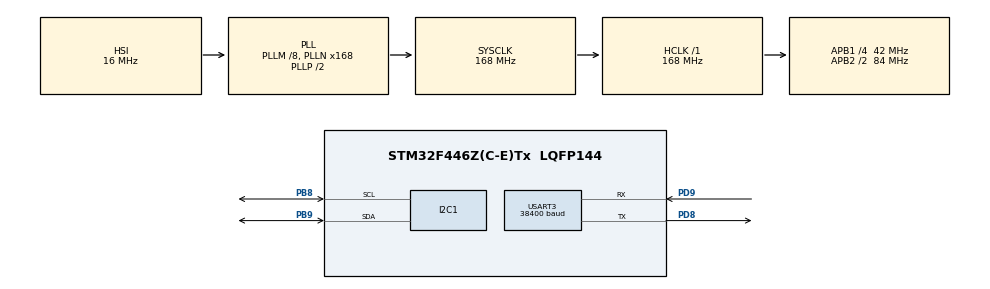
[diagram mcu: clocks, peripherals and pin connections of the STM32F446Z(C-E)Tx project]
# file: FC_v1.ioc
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FREERTOS.Tasks01=defaultTask,24,128,StartDefaultTask,Default,NULL,Dynamic,NULL,NULL;Iridium02,8,128,StartIridium02,Default,NULL,Dynamic,NULL,NULL;LSM6DSR03,8,128,StartLSM6DSR03,Default,NULL,Dynamic,NULL,NULL
FREERTOS.configUSE_NEWLIB_REENTRANT=1
Mcu.Family=STM32F4
Mcu.Name=STM32F446Z(C-E)Tx
Mcu.Package=LQFP144
NVIC.PriorityGroup=NVIC_PRIORITYGROUP_4
NVIC.RTC_Alarm_IRQn=true\:5\:0\:false\:false\:true\:true\:true\:true
NVIC.TIM1_UP_TIM10_IRQn=true\:15\:0\:false\:false\:true\:false\:false\:true
NVIC.TimeBase=TIM1_UP_TIM10_IRQn
NVIC.TimeBaseIP=TIM1
PB8.Mode=I2C
PB8.Signal=I2C1_SCL
PB9.Mode=I2C
PB9.Signal=I2C1_SDA
PD8.Mode=Asynchronous
PD8.Signal=USART3_TX
PD9.Mode=Asynchronous
PD9.Signal=USART3_RX
ProjectManager.HeapSize=0x200
ProjectManager.StackSize=0x400
ProjectManager.TargetToolchain=STM32CubeIDE
RCC.48MHZClocksFreq_Value=24000000
RCC.AHBFreq_Value=168000000
RCC.APB1CLKDivider=RCC_HCLK_DIV4
RCC.APB1Freq_Value=42000000
RCC.APB1TimFreq_Value=84000000
RCC.APB2CLKDivider=RCC_HCLK_DIV2
RCC.APB2Freq_Value=84000000
RCC.APB2TimFreq_Value=168000000
RCC.CortexFreq_Value=168000000
RCC.HCLKFreq_Value=168000000
RCC.HSE_VALUE=8000000
RCC.HSI_VALUE=16000000
RCC.PLLM=8
RCC.PLLMUL=RCC_PLL_MUL9
RCC.PLLN=168
RCC.PLLQ=7
RCC.PRESCALERUSB=RCC_USBCLKSOURCE_PLL_DIV1_5
RCC.SYSCLKFreq_VALUE=168000000
RCC.SYSCLKSource=RCC_SYSCLKSOURCE_PLLCLK
RCC.SYSCLKSourceVirtual=RCC_SYSCLKSOURCE_PLLCLK
RCC.USBFreq_Value=48000000
RCC.VCOOutputFreq_Value=336000000
RTC.Alarm=RTC_ALARM_A
RTC.Seconds_A=20
USART3.BaudRate=38400
USART3.VirtualMode=VM_ASYNC
VP_FREERTOS_VS_CMSIS_V2.Mode=CMSIS_V2
VP_RTC_VS_RTC_Activate.Mode=RTC_Enabled
VP_RTC_VS_RTC_Alarm_A_Intern.Mode=Alarm A
VP_RTC_VS_RTC_Calendar.Mode=RTC_Calendar
VP_SYS_VS_tim1.Mode=TIM1
board=NUCLEO-F446ZE

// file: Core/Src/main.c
/* USER CODE BEGIN Header */
/**
  ******************************************************************************
  * @file           : main.c
  * @brief          : Main program body
  ******************************************************************************
  * @attention
  *
  * <h2><center>&copy; Copyright (c) 2022 STMicroelectronics.
  * All rights reserved.</center></h2>
  *
  * This software component is licensed by ST under BSD 3-Clause license,
  * the "License"; You may not use this file except in compliance with the
  * License. You may obtain a copy of the License at:
  *                        opensource.org/licenses/BSD-3-Clause
  *
  ******************************************************************************
  */
/* USER CODE END Header */
#include "main.h"
#include "cmsis_os.h"

/* USER CODE BEGIN Includes */

#include <MRT_RTOS.h>
#include <IridiumSBD_Static_API.h>
#include <MRT_Helpers.h>
#include "lsm6dsr_reg.h"

/* USER CODE END Includes */

/* USER CODE BEGIN PD */

#define DIAGNOSTICS false

/* USER CODE END PD */

I2C_HandleTypeDef hi2c1;

RTC_HandleTypeDef hrtc;

UART_HandleTypeDef huart3;

/* Definitions for defaultTask */
osThreadId_t defaultTaskHandle;
const osThreadAttr_t defaultTask_attributes = {
  .name = "defaultTask",
  .stack_size = 128 * 4,
  .priority = (osPriority_t) osPriorityNormal,
};
/* Definitions for Iridium02 */
osThreadId_t Iridium02Handle;
const osThreadAttr_t Iridium02_attributes = {
  .name = "Iridium02",
  .stack_size = 128 * 4,
  .priority = (osPriority_t) osPriorityLow,
};
/* Definitions for LSM6DSR03 */
osThreadId_t LSM6DSR03Handle;
const osThreadAttr_t LSM6DSR03_attributes = {
  .name = "LSM6DSR03",
  .stack_size = 128 * 4,
  .priority = (osPriority_t) osPriorityLow,
};
/* USER CODE BEGIN PV */

osThreadId_t threadID[10];

/* USER CODE END PV */

void SystemClock_Config(void);
static void MX_GPIO_Init(void);
static void MX_USART3_UART_Init(void);
static void MX_RTC_Init(void);
static void MX_I2C1_Init(void);
void StartDefaultTask(void *argument);
void StartIridium02(void *argument);
void StartLSM6DSR03(void *argument);

int main(void)
{

  /* MCU Configuration--------------------------------------------------------*/

  /* Reset of all peripherals, Initializes the Flash interface and the Systick. */
  HAL_Init();

  /* Configure the system clock */
  SystemClock_Config();

  /* Initialize all configured peripherals */
  MX_GPIO_Init();
  MX_USART3_UART_Init();
  MX_RTC_Init();
  MX_I2C1_Init();
  /* USER CODE BEGIN 2 */

  checkForI2CDevices(huart3,hi2c1);

  //TODO
  /*
   * In general:
   *-Activate I2C1 and use pins PB8 and PB9
   *-Activate usart3 and use pins PD9 and PD8 and set the baud rate
   *-Activate freeRTOS
   *-Change SysTic to any other timer
   *-Include the path to all includes folders of the drivers (for C and C++ linkers)
   */

  /*
   * For Iridium:
   * -Set the project as c++
   */
  //MRT_Static_Iridium_Setup(huart3);

  /*
   * For LSM6DSR
   *-Enable float formatting for sprintf (go to Project->Properties->C/C++ Build->Settings->MCU Settings->Check the box "Use float with printf")
   */
  MRT_LSM6DSR_Setup(&huart3,hi2c1);

  /*
   * For RTOS
   * -Activate RTC, calendar and internal alarm A (don't forget to activate NVIC EXTI)
   * -Define what you want in the alarms callback functions (check the .h file)
   * -(Optional) Setup alarm A and the clock time in .ioc
   * The rest have been taken care of
   * You can access the flag of both alarm A and B with the variables flagA and flagB
   */
  MRT_SetupRTOS(huart3,10,0);

  HAL_UART_Transmit(&huart3,"Starting FC\r\n",13,HAL_MAX_DELAY);

  /* USER CODE END 2 */

  /* Init scheduler */
  osKernelInitialize();

  /* Create the thread(s) */
  /* creation of defaultTask */
  defaultTaskHandle = osThreadNew(StartDefaultTask, NULL, &defaultTask_attributes);

  /* creation of Iridium02 */
  Iridium02Handle = osThreadNew(StartIridium02, NULL, &Iridium02_attributes);

  /* creation of LSM6DSR03 */
  LSM6DSR03Handle = osThreadNew(StartLSM6DSR03, NULL, &LSM6DSR03_attributes);

  /* Start scheduler */
  osKernelStart();

  /* We should never get here as control is now taken by the scheduler */
  /* Infinite loop */
  while (1)
  {

  }
}

void SystemClock_Config(void)
{
  RCC_OscInitTypeDef RCC_OscInitStruct = {0};
  RCC_ClkInitTypeDef RCC_ClkInitStruct = {0};

  /** Configure the main internal regulator output voltage
  */
  __HAL_RCC_PWR_CLK_ENABLE();
  __HAL_PWR_VOLTAGESCALING_CONFIG(PWR_REGULATOR_VOLTAGE_SCALE1);
  /** Initializes the RCC Oscillators according to the specified parameters
  * in the RCC_OscInitTypeDef structure.
  */
  RCC_OscInitStruct.OscillatorType = RCC_OSCILLATORTYPE_HSI|RCC_OSCILLATORTYPE_LSI;
  RCC_OscInitStruct.LSEState = RCC_LSE_OFF;
  RCC_OscInitStruct.HSIState = RCC_HSI_ON;
  RCC_OscInitStruct.HSICalibrationValue = RCC_HSICALIBRATION_DEFAULT;
  RCC_OscInitStruct.LSIState = RCC_LSI_ON;
  RCC_OscInitStruct.PLL.PLLState = RCC_PLL_ON;
  RCC_OscInitStruct.PLL.PLLSource = RCC_PLLSOURCE_HSI;
  RCC_OscInitStruct.PLL.PLLM = 8;
  RCC_OscInitStruct.PLL.PLLN = 168;
  RCC_OscInitStruct.PLL.PLLP = RCC_PLLP_DIV2;
  RCC_OscInitStruct.PLL.PLLQ = 7;
  RCC_OscInitStruct.PLL.PLLR = 2;
  if (HAL_RCC_OscConfig(&RCC_OscInitStruct) != HAL_OK)
  {
    Error_Handler();
  }
  /** Initializes the CPU, AHB and APB buses clocks
  */
  RCC_ClkInitStruct.ClockType = RCC_CLOCKTYPE_HCLK|RCC_CLOCKTYPE_SYSCLK
                              |RCC_CLOCKTYPE_PCLK1|RCC_CLOCKTYPE_PCLK2;
  RCC_ClkInitStruct.SYSCLKSource = RCC_SYSCLKSOURCE_PLLCLK;
  RCC_ClkInitStruct.AHBCLKDivider = RCC_SYSCLK_DIV1;
  RCC_ClkInitStruct.APB1CLKDivider = RCC_HCLK_DIV4;
  RCC_ClkInitStruct.APB2CLKDivider = RCC_HCLK_DIV2;

  if (HAL_RCC_ClockConfig(&RCC_ClkInitStruct, FLASH_LATENCY_5) != HAL_OK)
  {
    Error_Handler();
  }
}

static void MX_I2C1_Init(void)
{

  hi2c1.Instance = I2C1;
  hi2c1.Init.ClockSpeed = 100000;
  hi2c1.Init.DutyCycle = I2C_DUTYCYCLE_2;
  hi2c1.Init.OwnAddress1 = 0;
  hi2c1.Init.AddressingMode = I2C_ADDRESSINGMODE_7BIT;
  hi2c1.Init.DualAddressMode = I2C_DUALADDRESS_DISABLE;
  hi2c1.Init.OwnAddress2 = 0;
  hi2c1.Init.GeneralCallMode = I2C_GENERALCALL_DISABLE;
  hi2c1.Init.NoStretchMode = I2C_NOSTRETCH_DISABLE;
  if (HAL_I2C_Init(&hi2c1) != HAL_OK)
  {
    Error_Handler();
  }

}

static void MX_RTC_Init(void)
{

  RTC_TimeTypeDef sTime = {0};
  RTC_DateTypeDef sDate = {0};
  RTC_AlarmTypeDef sAlarm = {0};

  /** Initialize RTC Only
  */
  hrtc.Instance = RTC;
  hrtc.Init.HourFormat = RTC_HOURFORMAT_24;
  hrtc.Init.AsynchPrediv = 127;
  hrtc.Init.SynchPrediv = 255;
  hrtc.Init.OutPut = RTC_OUTPUT_DISABLE;
  hrtc.Init.OutPutPolarity = RTC_OUTPUT_POLARITY_HIGH;
  hrtc.Init.OutPutType = RTC_OUTPUT_TYPE_OPENDRAIN;
  if (HAL_RTC_Init(&hrtc) != HAL_OK)
  {
    Error_Handler();
  }

  /** Initialize RTC and set the Time and Date
  */
  sTime.Hours = 0x0;
  sTime.Minutes = 0x0;
  sTime.Seconds = 0x0;
  sTime.DayLightSaving = RTC_DAYLIGHTSAVING_NONE;
  sTime.StoreOperation = RTC_STOREOPERATION_RESET;
  if (HAL_RTC_SetTime(&hrtc, &sTime, RTC_FORMAT_BCD) != HAL_OK)
  {
    Error_Handler();
  }
  sDate.WeekDay = RTC_WEEKDAY_MONDAY;
  sDate.Month = RTC_MONTH_JANUARY;
  sDate.Date = 0x1;
  sDate.Year = 0x0;

  if (HAL_RTC_SetDate(&hrtc, &sDate, RTC_FORMAT_BCD) != HAL_OK)
  {
    Error_Handler();
  }
  /** Enable the Alarm A
  */
  sAlarm.AlarmTime.Hours = 0x0;
  sAlarm.AlarmTime.Minutes = 0x0;
  sAlarm.AlarmTime.Seconds = 0x20;
  sAlarm.AlarmTime.SubSeconds = 0x0;
  sAlarm.AlarmTime.DayLightSaving = RTC_DAYLIGHTSAVING_NONE;
  sAlarm.AlarmTime.StoreOperation = RTC_STOREOPERATION_RESET;
  sAlarm.AlarmMask = RTC_ALARMMASK_NONE;
  sAlarm.AlarmSubSecondMask = RTC_ALARMSUBSECONDMASK_ALL;
  sAlarm.AlarmDateWeekDaySel = RTC_ALARMDATEWEEKDAYSEL_DATE;
  sAlarm.AlarmDateWeekDay = 0x1;
  sAlarm.Alarm = RTC_ALARM_A;
  if (HAL_RTC_SetAlarm_IT(&hrtc, &sAlarm, RTC_FORMAT_BCD) != HAL_OK)
  {
    Error_Handler();
  }

}

static void MX_USART3_UART_Init(void)
{

  huart3.Instance = USART3;
  huart3.Init.BaudRate = 38400;
  huart3.Init.WordLength = UART_WORDLENGTH_8B;
  huart3.Init.StopBits = UART_STOPBITS_1;
  huart3.Init.Parity = UART_PARITY_NONE;
  huart3.Init.Mode = UART_MODE_TX_RX;
  huart3.Init.HwFlowCtl = UART_HWCONTROL_NONE;
  huart3.Init.OverSampling = UART_OVERSAMPLING_16;
  if (HAL_UART_Init(&huart3) != HAL_OK)
  {
    Error_Handler();
  }

}

static void MX_GPIO_Init(void)
{

  /* GPIO Ports Clock Enable */
  __HAL_RCC_GPIOD_CLK_ENABLE();
  __HAL_RCC_GPIOB_CLK_ENABLE();

}

void StartDefaultTask(void *argument)
{
  /* USER CODE BEGIN 5 */

	//Add thread id to the list
	threadID[0]=osThreadGetId();

  /* Infinite loop */
  for(;;)
  {
	/*
	if (flagA==1){
		MRT_Static_Iridium_Shutdown();
		MRT_StandByMode(10);
	}
	*/
    osDelay(1);
  }

  //In case it leaves the infinite loop
  HAL_UART_Transmit(&huart3,"Something went wrong with thread 0\r\n",36,HAL_MAX_DELAY);
  osThreadTerminate(NULL);

  /* USER CODE END 5 */
}

void StartIridium02(void *argument)
{
  /* USER CODE BEGIN StartIridium02 */

	//Add thread id to the list
	threadID[2]=osThreadGetId();

	/*
	MRT_Static_Iridium_CSQ();
	MRT_Static_Iridium_getIMEI();

	while(MRT_Static_Iridium_NetworkAvailability()!=1) osDelay(1000);

  /* Infinite loop */
  for(;;)
  {
	//MRT_Static_Iridium_getTime();
    osDelay(5000);
  }

  //In case it leaves the infinite loop
  HAL_UART_Transmit(&huart3,"Something went wrong with thread 2\r\n",36,HAL_MAX_DELAY);
  osThreadTerminate(NULL);

  /* USER CODE END StartIridium02 */
}

void StartLSM6DSR03(void *argument)
{
  /* USER CODE BEGIN StartLSM6DSR03 */
	//Add thread id to the list
	threadID[3]=osThreadGetId();

  /* Infinite loop */
  for(;;)
  {
	osDelay(1000);
	LSM6DSR_getAcceleration(data_raw_acceleration,acceleration_mg,&dev_ctx);
	sprintf((char *)tx_buffer, "Acceleration [mg]:%4.2f\t%4.2f\t%4.2f\r\n",acceleration_mg[0], acceleration_mg[1], acceleration_mg[2]);
	HAL_UART_Transmit(&huart3, tx_buffer, strlen(tx_buffer), HAL_MAX_DELAY);

	LSM6DSR_getAngularRate(data_raw_angular_rate,angular_rate_mdps,&dev_ctx);
	sprintf((char *)tx_buffer,"Angular rate [mdps]:%4.2f\t%4.2f\t%4.2f\r\n",angular_rate_mdps[0], angular_rate_mdps[1], angular_rate_mdps[2]);
	HAL_UART_Transmit(&huart3, tx_buffer, strlen(tx_buffer), HAL_MAX_DELAY);

	LSM6DSR_getTemperature(data_raw_temperature,temperature_degC,&dev_ctx);
	sprintf((char *)tx_buffer, "Temperature [degC]:%6.2f\r\n", temperature_degC[0]);
	HAL_UART_Transmit(&huart3, tx_buffer, strlen(tx_buffer), HAL_MAX_DELAY);
  }

  //In case it leaves the infinite loop
  HAL_UART_Transmit(&huart3,"Something went wrong with thread 3\r\n",36,HAL_MAX_DELAY);
  osThreadTerminate(NULL);
  /* USER CODE END StartLSM6DSR03 */
}

void HAL_TIM_PeriodElapsedCallback(TIM_HandleTypeDef *htim)
{
  if (htim->Instance == TIM1) {
    HAL_IncTick();
  }
}

void Error_Handler(void)
{
  __disable_irq();
  while (1)
  {
  }
}

/************************ (C) COPYRIGHT STMicroelectronics *****END OF FILE****/
